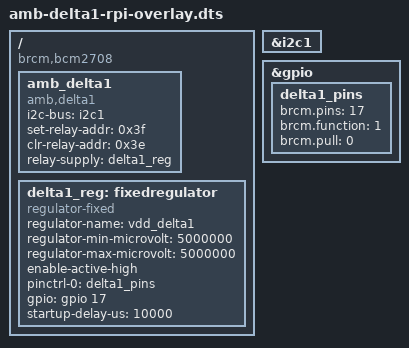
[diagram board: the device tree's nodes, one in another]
/dts-v1/;
/plugin/;

/ {
	compatible = "brcm,bcm2708";

	fragment@0 {
		target-path = "/";
		__overlay__ {
			amb_delta1: amb_delta1 {
				compatible = "amb,delta1";
				status = "okay";
				i2c-bus = <&i2c1>;
				set-relay-addr = <0x3f>;
				clr-relay-addr = <0x3e>;
				relay-supply = <&delta1_reg>;
			};
		};
	};

	fragment@1 {
		target = <&i2c1>;
		__overlay__ {
			status = "okay";
		};
	};

	fragment@2 {
		target-path = "/";
		__overlay__ {
			delta1_reg: fixedregulator {
				compatible = "regulator-fixed";
				regulator-name = "vdd_delta1";
				regulator-min-microvolt = <5000000>;
				regulator-max-microvolt = <5000000>;
				enable-active-high;
				pinctrl-names = "default";
				pinctrl-0 = <&delta1_pins>;
				gpio = <&gpio 17 0>;
				startup-delay-us = <10000>;
			};
		};
	};

	fragment@3 {
		target = <&gpio>;
		__overlay__ {
			delta1_pins: delta1_pins {
				brcm.pins = <17>;
				brcm.function = <1>;
				brcm.pull = <0>;
			};
		};
	};
};
